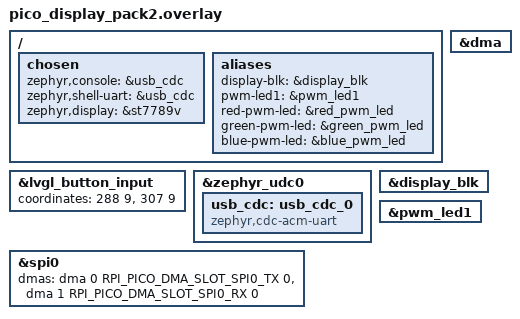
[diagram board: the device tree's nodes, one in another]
/*
 * Copyright (c) 2019 Creative Product Design
 *
 * SPDX-License-Identifier: Apache-2.0
 */
#include <zephyr/dt-bindings/pinctrl/rpi-pico-rp2040-pinctrl.h>
#include <zephyr/dt-bindings/dma/rpi-pico-dma-rp2040.h>
#include <zephyr/dt-bindings/mipi_dbi/mipi_dbi.h>
#include <zephyr/dt-bindings/input/input-event-codes.h>
#include <zephyr/dt-bindings/lvgl/lvgl.h>

#include "../common/pico_display_pack2_lcd.dtsi"
#include "../common/pico_display_pack_buttons.dtsi"
#include "../common/pico_display_pack_lvgl_input.dtsi"
#include "../common/pico_display_pack_leds.dtsi"
#include "../common/pico_display_pack_pwm_config.dtsi"

/ {
    chosen {
           zephyr,console = &usb_cdc;
	   zephyr,shell-uart = &usb_cdc;
	   zephyr,display = &st7789v;
	};

    aliases {
        display-blk = &display_blk;
        pwm-led1 = &pwm_led1;
	red-pwm-led = &red_pwm_led;
	green-pwm-led = &green_pwm_led;
	blue-pwm-led = &blue_pwm_led;
    };

};

&lvgl_button_input {
    coordinates = <288 9>, <307 9>;
};

&zephyr_udc0 {
	usb_cdc: usb_cdc_0 {
		compatible = "zephyr,cdc-acm-uart";
	};
};

&dma {
	status = "okay";
};

&spi0 {
	status = "okay";

	/* Feed the PL022 TX/RX FIFOs via DMA so frame flushes don't busy-wait
	 * the CPU. PL022 DMA path requires both tx and rx channels. */
	dmas = <&dma 0 RPI_PICO_DMA_SLOT_SPI0_TX 0>,
	       <&dma 1 RPI_PICO_DMA_SLOT_SPI0_RX 0>;
	dma-names = "tx", "rx";
};

/* Display backlight PWM. Use this project's own label (display_blk) rather
 * than &pwm_led0: the latter is defined only by the non-W board's
 * rpi_pico-led.dtsi, which rpi_pico/rp2040/w does not include. Both labels
 * name the same /pwm_leds/pwm_led_0 node, so this is a no-op on the plain
 * Pico and lets the overlay build on the Pico W. */
&display_blk {
	status = "okay";
};

&pwm_led1 {
	status = "okay";
};
